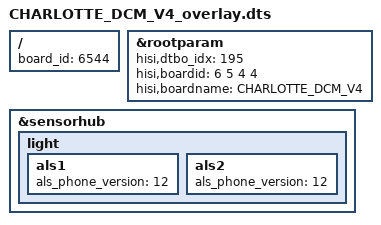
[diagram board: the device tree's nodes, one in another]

/**
 * Copyright (C) 2014 Hisilicon Ltd.
 *
 *  This program is free software; you can redistribute it and/or modify
 *  it under the terms of the GNU General Public License version 2 as
 *  publishhed by the Free Software Foundation.
 */

/dts-v1/;
/plugin/;
/include/ "CHARLOTTE_DCM_V3_overlay.dtsi"
/include/ "CHARLOTTE_DCM_V4_overlay_module_amba.dts"

/ {
        board_id = <6544>;
};

&rootparam {
        hisi,dtbo_idx = <195>;
    hisi,boardid = <6 5 4 4>;
    hisi,boardname = "CHARLOTTE_DCM_V4";
};


&sensorhub {
	light{
		als1{
			als_phone_version = <12>;
		};
		als2{
			als_phone_version = <12>;
		};
	};
};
